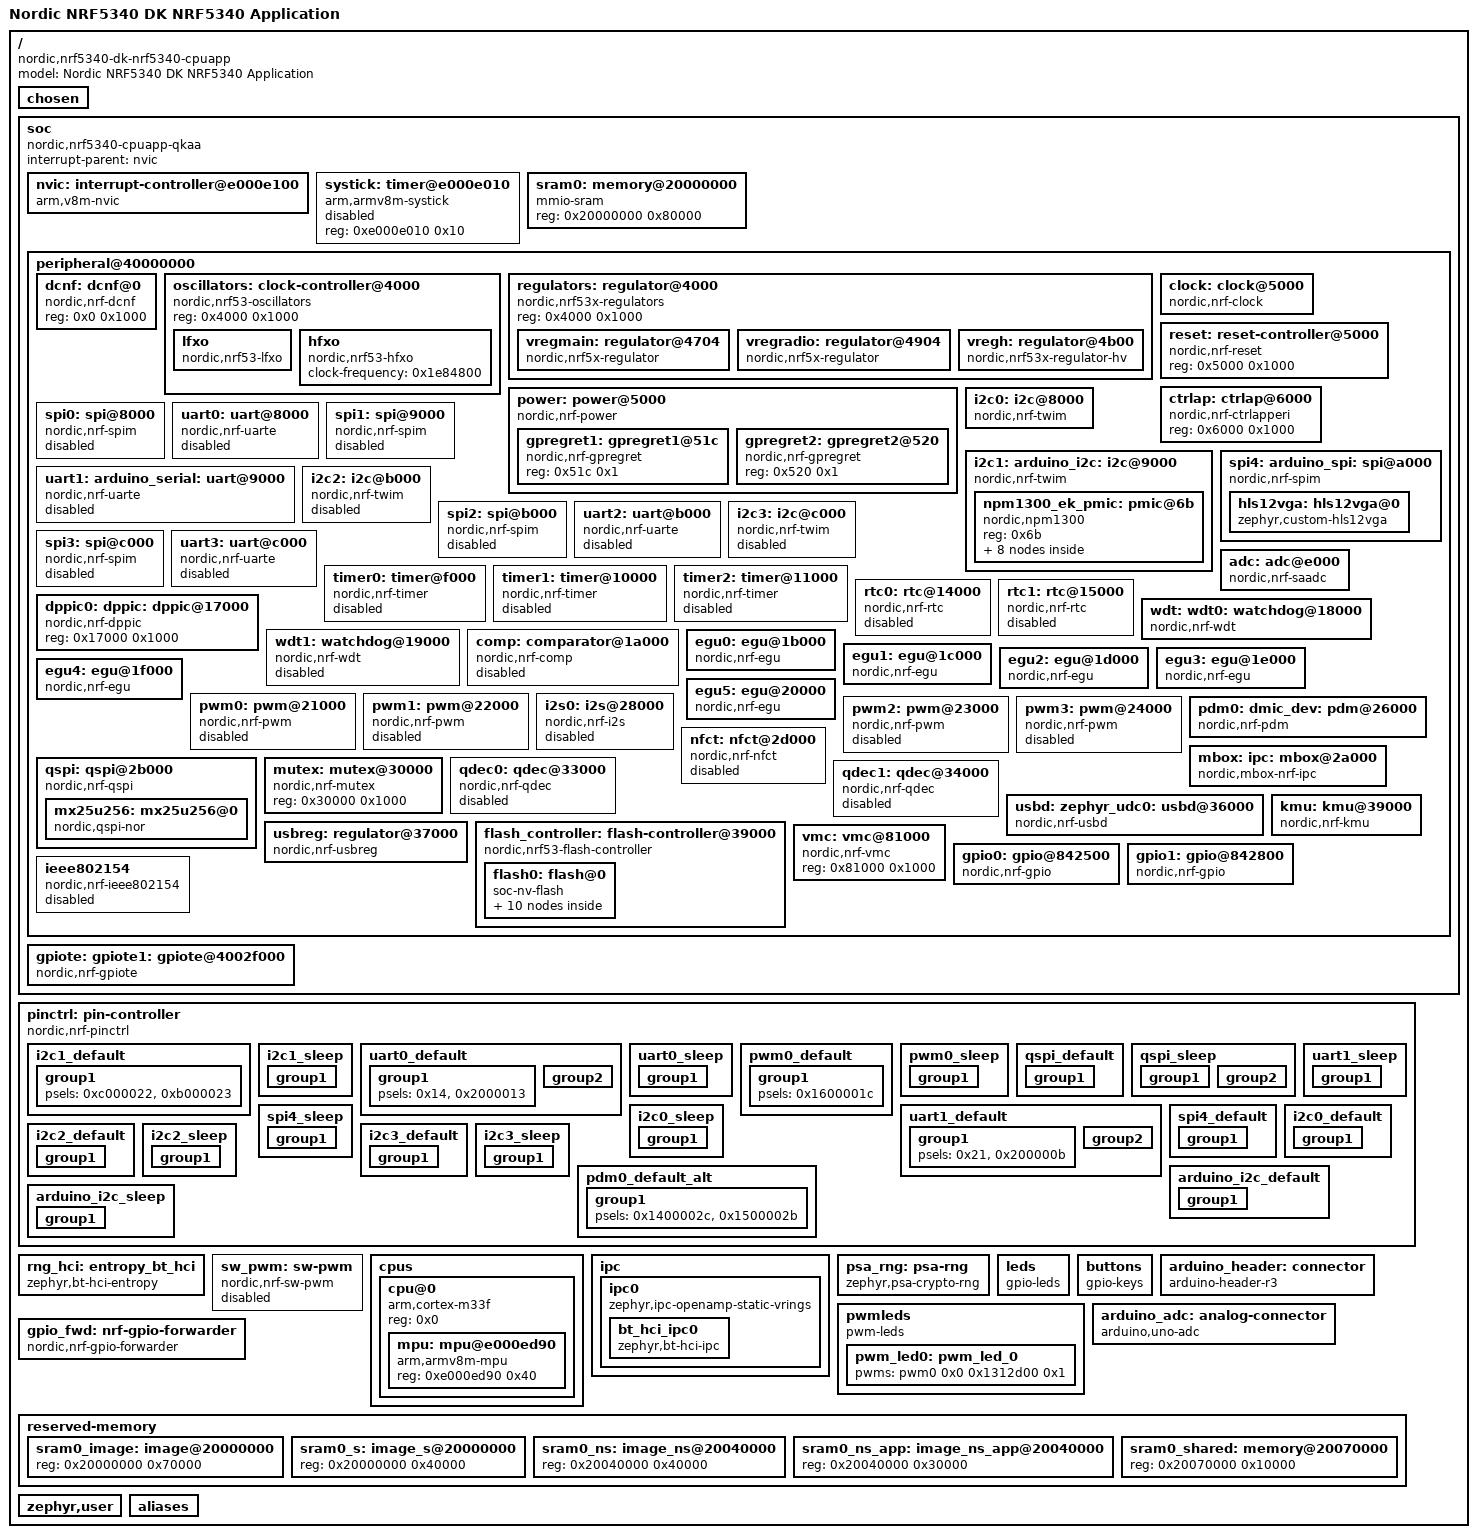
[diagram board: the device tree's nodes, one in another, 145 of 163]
/dts-v1/;

/ {
	#address-cells = < 0x1 >;
	#size-cells = < 0x1 >;
	model = "Nordic NRF5340 DK NRF5340 Application";
	compatible = "nordic,nrf5340-dk-nrf5340-cpuapp";
	chosen {
		zephyr,entropy = &psa_rng;
		zephyr,flash-controller = &flash_controller;
		zephyr,console = &uart0;
		zephyr,shell-uart = &uart0;
		zephyr,uart-mcumgr = &uart0;
		zephyr,bt-mon-uart = &uart0;
		zephyr,bt-c2h-uart = &uart0;
		zephyr,bt-hci = &bt_hci_ipc0;
		nordic,802154-spinel-ipc = &ipc0;
		zephyr,ieee802154 = &ieee802154;
		zephyr,ipc_shm = &sram0_shared;
		zephyr,sram = &sram0_ns_app;
		zephyr,flash = &flash0;
		zephyr,code-partition = &slot0_ns_partition;
		zephyr,display = &hls12vga;
		nordic,pm-ext-flash = &mx25u256;
	};
	soc {
		#address-cells = < 0x1 >;
		#size-cells = < 0x1 >;
		compatible = "nordic,nrf5340-cpuapp-qkaa", "nordic,nrf5340-cpuapp", "nordic,nrf53", "simple-bus";
		interrupt-parent = < &nvic >;
		ranges;
		nvic: interrupt-controller@e000e100 {
			#address-cells = < 0x1 >;
			compatible = "arm,v8m-nvic";
			reg = < 0xe000e100 0xc00 >;
			interrupt-controller;
			#interrupt-cells = < 0x2 >;
			arm,num-irq-priority-bits = < 0x3 >;
			phandle = < 0x1 >;
		};
		systick: timer@e000e010 {
			compatible = "arm,armv8m-systick";
			reg = < 0xe000e010 0x10 >;
			status = "disabled";
		};
		sram0: memory@20000000 {
			compatible = "mmio-sram";
			reg = < 0x20000000 0x80000 >;
		};
		peripheral@40000000 {
			#address-cells = < 0x1 >;
			#size-cells = < 0x1 >;
			ranges = < 0x0 0x40000000 0x10000000 >;
			dcnf: dcnf@0 {
				compatible = "nordic,nrf-dcnf";
				reg = < 0x0 0x1000 >;
				status = "okay";
			};
			oscillators: clock-controller@4000 {
				compatible = "nordic,nrf53-oscillators";
				reg = < 0x4000 0x1000 >;
				lfxo: lfxo {
					compatible = "nordic,nrf53-lfxo";
					#clock-cells = < 0x0 >;
					clock-frequency = < 0x8000 >;
					load-capacitors = "internal";
					load-capacitance-picofarad = < 0x7 >;
				};
				hfxo: hfxo {
					compatible = "nordic,nrf53-hfxo";
					#clock-cells = < 0x0 >;
					clock-frequency = < 0x1e84800 >;
				};
			};
			regulators: regulator@4000 {
				compatible = "nordic,nrf53x-regulators";
				reg = < 0x4000 0x1000 >;
				status = "okay";
				#address-cells = < 0x1 >;
				#size-cells = < 0x1 >;
				vregmain: regulator@4704 {
					compatible = "nordic,nrf5x-regulator";
					reg = < 0x4704 0x1 >;
					status = "okay";
					regulator-name = "VREGMAIN";
					regulator-initial-mode = < 0x1 >;
				};
				vregradio: regulator@4904 {
					compatible = "nordic,nrf5x-regulator";
					reg = < 0x4904 0x1 >;
					status = "okay";
					regulator-name = "VREGRADIO";
					regulator-initial-mode = < 0x1 >;
				};
				vregh: regulator@4b00 {
					compatible = "nordic,nrf53x-regulator-hv";
					reg = < 0x4b00 0x44 >;
					status = "okay";
					regulator-name = "VREGH";
				};
			};
			clock: clock@5000 {
				compatible = "nordic,nrf-clock";
				reg = < 0x5000 0x1000 >;
				interrupts = < 0x5 0x1 >;
				status = "okay";
			};
			power: power@5000 {
				compatible = "nordic,nrf-power";
				reg = < 0x5000 0x1000 >;
				ranges = < 0x0 0x5000 0x1000 >;
				interrupts = < 0x5 0x1 >;
				status = "okay";
				#address-cells = < 0x1 >;
				#size-cells = < 0x1 >;
				gpregret1: gpregret1@51c {
					#address-cells = < 0x1 >;
					#size-cells = < 0x1 >;
					compatible = "nordic,nrf-gpregret";
					reg = < 0x51c 0x1 >;
					status = "okay";
				};
				gpregret2: gpregret2@520 {
					#address-cells = < 0x1 >;
					#size-cells = < 0x1 >;
					compatible = "nordic,nrf-gpregret";
					reg = < 0x520 0x1 >;
					status = "okay";
				};
			};
			reset: reset-controller@5000 {
				compatible = "nordic,nrf-reset";
				reg = < 0x5000 0x1000 >;
				status = "okay";
			};
			ctrlap: ctrlap@6000 {
				compatible = "nordic,nrf-ctrlapperi";
				reg = < 0x6000 0x1000 >;
				status = "okay";
			};
			i2c0: i2c@8000 {
				compatible = "nordic,nrf-twim";
				#address-cells = < 0x1 >;
				#size-cells = < 0x0 >;
				reg = < 0x8000 0x1000 >;
				interrupts = < 0x8 0x1 >;
				easydma-maxcnt-bits = < 0x10 >;
				status = "okay";
				zephyr,pm-device-runtime-auto;
				pinctrl-0 = < &i2c0_default >;
				pinctrl-1 = < &i2c0_sleep >;
				pinctrl-names = "default", "sleep";
			};
			spi0: spi@8000 {
				compatible = "nordic,nrf-spim";
				#address-cells = < 0x1 >;
				#size-cells = < 0x0 >;
				reg = < 0x8000 0x1000 >;
				interrupts = < 0x8 0x1 >;
				max-frequency = < 0x7a1200 >;
				easydma-maxcnt-bits = < 0x10 >;
				status = "disabled";
			};
			uart0: uart@8000 {
				compatible = "nordic,nrf-uarte";
				reg = < 0x8000 0x1000 >;
				interrupts = < 0x8 0x1 >;
				status = "disabled";
				current-speed = < 0x1c200 >;
				pinctrl-0 = < &uart0_default >;
				pinctrl-1 = < &uart0_sleep >;
				pinctrl-names = "default", "sleep";
			};
			i2c1: arduino_i2c: i2c@9000 {
				compatible = "nordic,nrf-twim";
				#address-cells = < 0x1 >;
				#size-cells = < 0x0 >;
				reg = < 0x9000 0x1000 >;
				interrupts = < 0x9 0x1 >;
				easydma-maxcnt-bits = < 0x10 >;
				status = "okay";
				zephyr,pm-device-runtime-auto;
				pinctrl-0 = < &arduino_i2c_default >;
				pinctrl-1 = < &arduino_i2c_sleep >;
				pinctrl-names = "default", "sleep";
				clock-frequency = < 0x186a0 >;
				npm1300_ek_pmic: pmic@6b {
					compatible = "nordic,npm1300";
					reg = < 0x6b >;
					npm1300_ek_gpio: gpio-controller {
						compatible = "nordic,npm1300-gpio";
						gpio-controller;
						#gpio-cells = < 0x2 >;
						ngpios = < 0x5 >;
					};
					npm1300_ek_regulators: regulators {
						compatible = "nordic,npm1300-regulator";
						npm1300_ek_buck1: BUCK1 {
							regulator-min-microvolt = < 0xf4240 >;
							regulator-max-microvolt = < 0x325aa0 >;
							retention-microvolt = < 0x124f80 >;
						};
						npm1300_ek_buck2: BUCK2 {
							regulator-min-microvolt = < 0xf4240 >;
							regulator-max-microvolt = < 0x325aa0 >;
							retention-microvolt = < 0x1b7740 >;
						};
						npm1300_ek_ldo1: LDO1 {
							regulator-min-microvolt = < 0xf4240 >;
							regulator-max-microvolt = < 0x325aa0 >;
							regulator-initial-mode = < 0x3 >;
							regulator-boot-on;
						};
						npm1300_ek_ldo2: LDO2 {
							regulator-min-microvolt = < 0xf4240 >;
							regulator-max-microvolt = < 0x325aa0 >;
							regulator-initial-mode = < 0x3 >;
							regulator-boot-on;
						};
					};
					npm1300_ek_charger: charger {
						compatible = "nordic,npm1300-charger";
						term-microvolt = < 0x40d990 >;
						term-warm-microvolt = < 0x36ee80 >;
						current-microamp = < 0xc3500 >;
						dischg-limit-microamp = < 0x30d40 >;
						vbus-limit-microamp = < 0x7a120 >;
						thermistor-ohms = < 0x2710 >;
						thermistor-beta = < 0xd34 >;
						charging-enable;
						vbatlow-charge-enable;
					};
					npm1300_ek_leds: leds {
						compatible = "nordic,npm1300-led";
						nordic,led0-mode = "error";
						nordic,led1-mode = "charging";
						nordic,led2-mode = "host";
					};
				};
			};
			spi1: spi@9000 {
				compatible = "nordic,nrf-spim";
				#address-cells = < 0x1 >;
				#size-cells = < 0x0 >;
				reg = < 0x9000 0x1000 >;
				interrupts = < 0x9 0x1 >;
				max-frequency = < 0x7a1200 >;
				easydma-maxcnt-bits = < 0x10 >;
				status = "disabled";
			};
			uart1: arduino_serial: uart@9000 {
				compatible = "nordic,nrf-uarte";
				reg = < 0x9000 0x1000 >;
				interrupts = < 0x9 0x1 >;
				status = "disabled";
				current-speed = < 0x1c200 >;
				pinctrl-0 = < &uart1_default >;
				pinctrl-1 = < &uart1_sleep >;
				pinctrl-names = "default", "sleep";
			};
			spi4: arduino_spi: spi@a000 {
				compatible = "nordic,nrf-spim";
				#address-cells = < 0x1 >;
				#size-cells = < 0x0 >;
				reg = < 0xa000 0x1000 >;
				interrupts = < 0xa 0x1 >;
				max-frequency = < 0x1e84800 >;
				easydma-maxcnt-bits = < 0x10 >;
				rx-delay-supported;
				rx-delay = < 0x2 >;
				status = "okay";
				cs-gpios = < &gpio0 0x0 0x0 >;
				pinctrl-0 = < &spi4_default >;
				pinctrl-1 = < &spi4_sleep >;
				pinctrl-names = "default", "sleep";
				hls12vga: hls12vga@0 {
					compatible = "zephyr,custom-hls12vga";
					status = "okay";
					reg = < 0x0 >;
					spi-max-frequency = < 0x1e84800 >;
					left_cs-gpios = < &gpio0 0xb 0x0 >;
					right_cs-gpios = < &gpio0 0xc 0x0 >;
					reset-gpios = < &gpio1 0x1 0x0 >;
					vcom-gpios = < &gpio0 0x7 0x0 >;
					v1_8-gpios = < &gpio0 0x6 0x0 >;
					v0_9-gpios = < &gpio0 0x5 0x0 >;
					width = < 0x280 >;
					height = < 0x1e0 >;
				};
			};
			i2c2: i2c@b000 {
				compatible = "nordic,nrf-twim";
				#address-cells = < 0x1 >;
				#size-cells = < 0x0 >;
				reg = < 0xb000 0x1000 >;
				interrupts = < 0xb 0x1 >;
				easydma-maxcnt-bits = < 0x10 >;
				status = "disabled";
				zephyr,pm-device-runtime-auto;
				pinctrl-0 = < &i2c2_default >;
				pinctrl-1 = < &i2c2_sleep >;
				pinctrl-names = "default", "sleep";
			};
			spi2: spi@b000 {
				compatible = "nordic,nrf-spim";
				#address-cells = < 0x1 >;
				#size-cells = < 0x0 >;
				reg = < 0xb000 0x1000 >;
				interrupts = < 0xb 0x1 >;
				max-frequency = < 0x7a1200 >;
				easydma-maxcnt-bits = < 0x10 >;
				status = "disabled";
			};
			uart2: uart@b000 {
				compatible = "nordic,nrf-uarte";
				reg = < 0xb000 0x1000 >;
				interrupts = < 0xb 0x1 >;
				status = "disabled";
			};
			i2c3: i2c@c000 {
				compatible = "nordic,nrf-twim";
				#address-cells = < 0x1 >;
				#size-cells = < 0x0 >;
				reg = < 0xc000 0x1000 >;
				interrupts = < 0xc 0x1 >;
				easydma-maxcnt-bits = < 0x10 >;
				status = "disabled";
				zephyr,pm-device-runtime-auto;
				pinctrl-0 = < &i2c3_default >;
				pinctrl-1 = < &i2c3_sleep >;
				pinctrl-names = "default", "sleep";
			};
			spi3: spi@c000 {
				compatible = "nordic,nrf-spim";
				#address-cells = < 0x1 >;
				#size-cells = < 0x0 >;
				reg = < 0xc000 0x1000 >;
				interrupts = < 0xc 0x1 >;
				max-frequency = < 0x7a1200 >;
				easydma-maxcnt-bits = < 0x10 >;
				status = "disabled";
			};
			uart3: uart@c000 {
				compatible = "nordic,nrf-uarte";
				reg = < 0xc000 0x1000 >;
				interrupts = < 0xc 0x1 >;
				status = "disabled";
			};
			adc: adc@e000 {
				compatible = "nordic,nrf-saadc";
				reg = < 0xe000 0x1000 >;
				interrupts = < 0xe 0x1 >;
				status = "okay";
				#io-channel-cells = < 0x1 >;
				zephyr,pm-device-runtime-auto;
				phandle = < 0x1c >;
			};
			timer0: timer@f000 {
				compatible = "nordic,nrf-timer";
				status = "disabled";
				reg = < 0xf000 0x1000 >;
				cc-num = < 0x6 >;
				max-bit-width = < 0x20 >;
				interrupts = < 0xf 0x1 >;
				prescaler = < 0x0 >;
			};
			timer1: timer@10000 {
				compatible = "nordic,nrf-timer";
				status = "disabled";
				reg = < 0x10000 0x1000 >;
				cc-num = < 0x6 >;
				max-bit-width = < 0x20 >;
				interrupts = < 0x10 0x1 >;
				prescaler = < 0x0 >;
				phandle = < 0x18 >;
			};
			timer2: timer@11000 {
				compatible = "nordic,nrf-timer";
				status = "disabled";
				reg = < 0x11000 0x1000 >;
				cc-num = < 0x6 >;
				max-bit-width = < 0x20 >;
				interrupts = < 0x11 0x1 >;
				prescaler = < 0x0 >;
			};
			rtc0: rtc@14000 {
				compatible = "nordic,nrf-rtc";
				reg = < 0x14000 0x1000 >;
				cc-num = < 0x4 >;
				interrupts = < 0x14 0x1 >;
				status = "disabled";
				clock-frequency = < 0x8000 >;
				prescaler = < 0x1 >;
			};
			rtc1: rtc@15000 {
				compatible = "nordic,nrf-rtc";
				reg = < 0x15000 0x1000 >;
				cc-num = < 0x4 >;
				interrupts = < 0x15 0x1 >;
				status = "disabled";
				clock-frequency = < 0x8000 >;
				prescaler = < 0x1 >;
			};
			dppic0: dppic: dppic@17000 {
				compatible = "nordic,nrf-dppic";
				reg = < 0x17000 0x1000 >;
				status = "okay";
			};
			wdt: wdt0: watchdog@18000 {
				compatible = "nordic,nrf-wdt";
				reg = < 0x18000 0x1000 >;
				interrupts = < 0x18 0x1 >;
				status = "okay";
			};
			wdt1: watchdog@19000 {
				compatible = "nordic,nrf-wdt";
				reg = < 0x19000 0x1000 >;
				interrupts = < 0x19 0x1 >;
				status = "disabled";
			};
			comp: comparator@1a000 {
				compatible = "nordic,nrf-comp";
				reg = < 0x1a000 0x1000 >;
				interrupts = < 0x1a 0x1 >;
				status = "disabled";
			};
			egu0: egu@1b000 {
				compatible = "nordic,nrf-egu";
				reg = < 0x1b000 0x1000 >;
				interrupts = < 0x1b 0x1 >;
				status = "okay";
			};
			egu1: egu@1c000 {
				compatible = "nordic,nrf-egu";
				reg = < 0x1c000 0x1000 >;
				interrupts = < 0x1c 0x1 >;
				status = "okay";
			};
			egu2: egu@1d000 {
				compatible = "nordic,nrf-egu";
				reg = < 0x1d000 0x1000 >;
				interrupts = < 0x1d 0x1 >;
				status = "okay";
			};
			egu3: egu@1e000 {
				compatible = "nordic,nrf-egu";
				reg = < 0x1e000 0x1000 >;
				interrupts = < 0x1e 0x1 >;
				status = "okay";
			};
			egu4: egu@1f000 {
				compatible = "nordic,nrf-egu";
				reg = < 0x1f000 0x1000 >;
				interrupts = < 0x1f 0x1 >;
				status = "okay";
			};
			egu5: egu@20000 {
				compatible = "nordic,nrf-egu";
				reg = < 0x20000 0x1000 >;
				interrupts = < 0x20 0x1 >;
				status = "okay";
			};
			pwm0: pwm@21000 {
				compatible = "nordic,nrf-pwm";
				reg = < 0x21000 0x1000 >;
				interrupts = < 0x21 0x1 >;
				status = "disabled";
				#pwm-cells = < 0x3 >;
				pinctrl-0 = < &pwm0_default >;
				pinctrl-1 = < &pwm0_sleep >;
				pinctrl-names = "default", "sleep";
				phandle = < 0x1b >;
			};
			pwm1: pwm@22000 {
				compatible = "nordic,nrf-pwm";
				reg = < 0x22000 0x1000 >;
				interrupts = < 0x22 0x1 >;
				status = "disabled";
				#pwm-cells = < 0x3 >;
			};
			pwm2: pwm@23000 {
				compatible = "nordic,nrf-pwm";
				reg = < 0x23000 0x1000 >;
				interrupts = < 0x23 0x1 >;
				status = "disabled";
				#pwm-cells = < 0x3 >;
			};
			pwm3: pwm@24000 {
				compatible = "nordic,nrf-pwm";
				reg = < 0x24000 0x1000 >;
				interrupts = < 0x24 0x1 >;
				status = "disabled";
				#pwm-cells = < 0x3 >;
			};
			pdm0: dmic_dev: pdm@26000 {
				compatible = "nordic,nrf-pdm";
				reg = < 0x26000 0x1000 >;
				interrupts = < 0x26 0x1 >;
				status = "okay";
				pinctrl-0 = < &pdm0_default_alt >;
				pinctrl-names = "default";
			};
			i2s0: i2s@28000 {
				compatible = "nordic,nrf-i2s";
				#address-cells = < 0x1 >;
				#size-cells = < 0x0 >;
				reg = < 0x28000 0x1000 >;
				interrupts = < 0x28 0x1 >;
				status = "disabled";
			};
			mbox: ipc: mbox@2a000 {
				compatible = "nordic,mbox-nrf-ipc", "nordic,nrf-ipc";
				reg = < 0x2a000 0x1000 >;
				tx-mask = < 0xffff >;
				rx-mask = < 0xffff >;
				interrupts = < 0x2a 0x1 >;
				#mbox-cells = < 0x1 >;
				status = "okay";
				phandle = < 0x1a >;
			};
			qspi: qspi@2b000 {
				compatible = "nordic,nrf-qspi";
				#address-cells = < 0x1 >;
				#size-cells = < 0x0 >;
				reg = < 0x2b000 0x1000 >, < 0x10000000 0x10000000 >;
				reg-names = "qspi", "qspi_mm";
				interrupts = < 0x2b 0x1 >;
				status = "okay";
				pinctrl-0 = < &qspi_default >;
				pinctrl-1 = < &qspi_sleep >;
				pinctrl-names = "default", "sleep";
				mx25u256: mx25u256@0 {
					compatible = "nordic,qspi-nor";
					reg = < 0x0 >;
					writeoc = "pp4io";
					readoc = "read4io";
					sck-frequency = < 0x1e84800 >;
					address-size-32;
					enter-4byte-addr = < 0xb7 >;
					jedec-id = [ C2 25 39 ];
					sfdp-bfp = [ E5 20 FB FF FF FF FF 0F 44 EB 08 6B 08 3B 04 BB FE FF FF FF FF FF 00 FF FF FF 44 EB 0C 20 0F 52 10 D8 00 FF 25 52 DD 00 84 A5 04 E2 44 03 17 38 30 B0 30 B0 F7 BD D5 5C 4A 9E 29 FF F0 50 F9 85 ];
					size = < 0x2000000 >;
					has-dpd;
					t-enter-dpd = < 0x2710 >;
					t-exit-dpd = < 0x88b8 >;
				};
			};
			nfct: nfct@2d000 {
				compatible = "nordic,nrf-nfct";
				reg = < 0x2d000 0x1000 >;
				interrupts = < 0x2d 0x1 >;
				status = "disabled";
			};
			mutex: mutex@30000 {
				compatible = "nordic,nrf-mutex";
				reg = < 0x30000 0x1000 >;
				status = "okay";
			};
			qdec0: qdec@33000 {
				compatible = "nordic,nrf-qdec";
				reg = < 0x33000 0x1000 >;
				interrupts = < 0x33 0x1 >;
				status = "disabled";
			};
			qdec1: qdec@34000 {
				compatible = "nordic,nrf-qdec";
				reg = < 0x34000 0x1000 >;
				interrupts = < 0x34 0x1 >;
				status = "disabled";
			};
			usbd: zephyr_udc0: usbd@36000 {
				compatible = "nordic,nrf-usbd";
				reg = < 0x36000 0x1000 >;
				interrupts = < 0x36 0x1 >;
				num-bidir-endpoints = < 0x1 >;
				num-in-endpoints = < 0x7 >;
				num-out-endpoints = < 0x7 >;
				num-isoin-endpoints = < 0x1 >;
				num-isoout-endpoints = < 0x1 >;
				status = "okay";
			};
			usbreg: regulator@37000 {
				compatible = "nordic,nrf-usbreg";
				reg = < 0x37000 0x1000 >;
				interrupts = < 0x37 0x1 >;
				status = "okay";
			};
			flash_controller: flash-controller@39000 {
				compatible = "nordic,nrf53-flash-controller";
				reg = < 0x39000 0x1000 >;
				partial-erase;
				#address-cells = < 0x1 >;
				#size-cells = < 0x1 >;
				flash0: flash@0 {
					compatible = "soc-nv-flash";
					erase-block-size = < 0x1000 >;
					write-block-size = < 0x4 >;
					reg = < 0x0 0x100000 >;
					partitions {
						compatible = "fixed-partitions";
						#address-cells = < 0x1 >;
						#size-cells = < 0x1 >;
						boot_partition: partition@0 {
							label = "mcuboot";
							reg = < 0x0 0x10000 >;
						};
						slot0_partition: partition@10000 {
							label = "image-0";
							reg = < 0x10000 0x40000 >;
						};
						slot0_ns_partition: partition@50000 {
							label = "image-0-nonsecure";
							reg = < 0x50000 0x30000 >;
						};
						slot1_partition: partition@80000 {
							label = "image-1";
							reg = < 0x80000 0x40000 >;
						};
						slot1_ns_partition: partition@c0000 {
							label = "image-1-nonsecure";
							reg = < 0xc0000 0x30000 >;
						};
						tfm_ps_partition: partition@f0000 {
							label = "tfm-ps";
							reg = < 0xf0000 0x4000 >;
						};
						tfm_its_partition: partition@f4000 {
							label = "tfm-its";
							reg = < 0xf4000 0x2000 >;
						};
						tfm_otp_partition: partition@f6000 {
							label = "tfm-otp";
							reg = < 0xf6000 0x2000 >;
						};
						storage_partition: partition@f8000 {
							label = "storage";
							reg = < 0xf8000 0x8000 >;
						};
					};
				};
			};
			kmu: kmu@39000 {
				compatible = "nordic,nrf-kmu";
				reg = < 0x39000 0x1000 >;
				interrupts = < 0x39 0x1 >;
				status = "okay";
			};
			vmc: vmc@81000 {
				compatible = "nordic,nrf-vmc";
				reg = < 0x81000 0x1000 >;
				status = "okay";
			};
			gpio0: gpio@842500 {
				compatible = "nordic,nrf-gpio";
				gpio-controller;
				reg = < 0x842500 0x300 >;
				#gpio-cells = < 0x2 >;
				status = "okay";
				port = < 0x0 >;
				gpiote-instance = < &gpiote >;
				sense-edge-mask = < 0xffffffff >;
				phandle = < 0xa >;
			};
			gpio1: gpio@842800 {
				compatible = "nordic,nrf-gpio";
				gpio-controller;
				reg = < 0x842800 0x300 >;
				#gpio-cells = < 0x2 >;
				ngpios = < 0x10 >;
				status = "okay";
				port = < 0x1 >;
				gpiote-instance = < &gpiote >;
				sense-edge-mask = < 0xffffffff >;
				phandle = < 0xd >;
			};
			ieee802154: ieee802154 {
				compatible = "nordic,nrf-ieee802154";
				status = "disabled";
			};
		};
		gpiote: gpiote1: gpiote@4002f000 {
			compatible = "nordic,nrf-gpiote";
			reg = < 0x4002f000 0x1000 >;
			interrupts = < 0x2f 0x5 >;
			status = "okay";
			instance = < 0x1 >;
			phandle = < 0x17 >;
		};
	};
	pinctrl: pin-controller {
		compatible = "nordic,nrf-pinctrl";
		i2c1_default: i2c1_default {
			group1 {
				psels = < 0xc000022 >, < 0xb000023 >;
			};
		};
		i2c1_sleep: i2c1_sleep {
			group1 {
				psels = < 0xc000022 >, < 0xb000023 >;
				low-power-enable;
			};
		};
		uart0_default: uart0_default {
			phandle = < 0x4 >;
			group1 {
				psels = < 0x14 >, < 0x2000013 >;
			};
			group2 {
				psels = < 0x1000016 >, < 0x3000015 >;
				bias-pull-up;
			};
		};
		uart0_sleep: uart0_sleep {
			phandle = < 0x5 >;
			group1 {
				psels = < 0x14 >, < 0x1000016 >, < 0x2000013 >, < 0x3000015 >;
				low-power-enable;
			};
		};
		pwm0_default: pwm0_default {
			phandle = < 0x12 >;
			group1 {
				psels = < 0x1600001c >;
			};
		};
		pwm0_sleep: pwm0_sleep {
			phandle = < 0x13 >;
			group1 {
				psels = < 0x1600001c >;
				low-power-enable;
			};
		};
		qspi_default: qspi_default {
			phandle = < 0x15 >;
			group1 {
				psels = < 0x1d000011 >, < 0x1f00000d >, < 0x2000000e >, < 0x2100000f >, < 0x22000010 >, < 0x1e000012 >;
				nordic,drive-mode = < 0x3 >;
			};
		};
		qspi_sleep: qspi_sleep {
			phandle = < 0x16 >;
			group1 {
				psels = < 0x1d000011 >, < 0x1f00000d >, < 0x2000000e >, < 0x2100000f >, < 0x22000010 >;
				low-power-enable;
			};
			group2 {
				psels = < 0x1e000012 >;
				low-power-enable;
				bias-pull-up;
			};
		};
		uart1_default: uart1_default {
			phandle = < 0x8 >;
			group1 {
				psels = < 0x21 >, < 0x200000b >;
			};
			group2 {
				psels = < 0x1000020 >, < 0x300000a >;
				bias-pull-up;
			};
		};
		uart1_sleep: uart1_sleep {
			phandle = < 0x9 >;
			group1 {
				psels = < 0x21 >, < 0x1000020 >, < 0x200000b >, < 0x300000a >;
				low-power-enable;
			};
		};
		spi4_default: spi4_default {
			phandle = < 0xb >;
			group1 {
				psels = < 0x4000008 >, < 0x600000a >, < 0x5000009 >;
				nordic,drive-mode = < 0x8 >;
			};
		};
		spi4_sleep: spi4_sleep {
			phandle = < 0xc >;
			group1 {
				psels = < 0x4000008 >, < 0x600000a >, < 0x5000009 >;
				low-power-enable;
			};
		};
		i2c0_default: i2c0_default {
			phandle = < 0x2 >;
			group1 {
				psels = < 0xc00001f >, < 0xb00001e >;
				bias-pull-up;
				nordic,drive-mode = < 0x6 >;
			};
		};
		i2c0_sleep: i2c0_sleep {
			phandle = < 0x3 >;
			group1 {
				psels = < 0xc00001f >, < 0xb00001e >;
				low-power-enable;
			};
		};
		i2c2_default: i2c2_default {
			phandle = < 0xe >;
			group1 {
				psels = < 0xc00002f >, < 0xb00002e >;
				bias-pull-up;
				nordic,drive-mode = < 0x6 >;
			};
		};
		i2c2_sleep: i2c2_sleep {
			phandle = < 0xf >;
			group1 {
				psels = < 0xc00002f >, < 0xb00002e >;
				low-power-enable;
			};
		};
		i2c3_default: i2c3_default {
			phandle = < 0x10 >;
			group1 {
				psels = < 0xc000024 >, < 0xb000025 >;
				bias-pull-up;
				nordic,drive-mode = < 0x6 >;
			};
		};
		i2c3_sleep: i2c3_sleep {
			phandle = < 0x11 >;
			group1 {
				psels = < 0xc000024 >, < 0xb000025 >;
				low-power-enable;
			};
		};
		pdm0_default_alt: pdm0_default_alt {
			phandle = < 0x14 >;
			group1 {
				psels = < 0x1400002c >, < 0x1500002b >;
			};
		};
		arduino_i2c_default: arduino_i2c_default {
			phandle = < 0x6 >;
			group1 {
				psels = < 0xb00001d >, < 0xc00002a >;
				bias-pull-up;
			};
		};
		arduino_i2c_sleep: arduino_i2c_sleep {
			phandle = < 0x7 >;
			group1 {
				psels = < 0xb00001d >, < 0xc00002a >;
				low-power-enable;
			};
		};
	};
	rng_hci: entropy_bt_hci {
		compatible = "zephyr,bt-hci-entropy";
		status = "okay";
	};
	sw_pwm: sw-pwm {
		compatible = "nordic,nrf-sw-pwm";
		status = "disabled";
		generator = < &timer1 >;
		clock-prescaler = < 0x0 >;
		#pwm-cells = < 0x3 >;
	};
	cpus {
		#address-cells = < 0x1 >;
		#size-cells = < 0x0 >;
		cpu@0 {
			device_type = "cpu";
			compatible = "arm,cortex-m33f";
			reg = < 0x0 >;
			#address-cells = < 0x1 >;
			#size-cells = < 0x1 >;
			mpu: mpu@e000ed90 {
				compatible = "arm,armv8m-mpu";
				reg = < 0xe000ed90 0x40 >;
			};
		};
	};
	ipc {
		ipc0: ipc0 {
			compatible = "zephyr,ipc-openamp-static-vrings";
			memory-region = < &sram0_shared >;
			mboxes = < &mbox 0x0 >, < &mbox 0x1 >;
			mbox-names = "tx", "rx";
			role = "host";
			status = "okay";
			bt_hci_ipc0: bt_hci_ipc0 {
				compatible = "zephyr,bt-hci-ipc";
				status = "okay";
			};
		};
	};
	psa_rng: psa-rng {
		compatible = "zephyr,psa-crypto-rng";
		status = "okay";
	};
	leds {
		compatible = "gpio-leds";
	};
	buttons {
		compatible = "gpio-keys";
	};
	arduino_header: connector {
		compatible = "arduino-header-r3";
		#gpio-cells = < 0x2 >;
		gpio-map-mask = < 0xffffffff 0xffffffc0 >;
		gpio-map-pass-thru = < 0x0 0x3f >;
		gpio-map = < 0x0 0x0 &gpio0 0x4 0x0 >, < 0x1 0x0 &gpio0 0x5 0x0 >, < 0x2 0x0 &gpio0 0x6 0x0 >, < 0x3 0x0 &gpio0 0x7 0x0 >, < 0x4 0x0 &gpio0 0x19 0x0 >, < 0x5 0x0 &gpio0 0x1a 0x0 >, < 0x6 0x0 &gpio1 0x0 0x0 >, < 0x7 0x0 &gpio1 0x1 0x0 >, < 0x8 0x0 &gpio1 0x4 0x0 >, < 0x9 0x0 &gpio1 0x5 0x0 >, < 0xa 0x0 &gpio1 0x6 0x0 >, < 0xb 0x0 &gpio1 0x7 0x0 >, < 0xc 0x0 &gpio1 0x8 0x0 >, < 0xd 0x0 &gpio1 0x9 0x0 >, < 0xe 0x0 &gpio1 0xa 0x0 >, < 0xf 0x0 &gpio1 0xb 0x0 >, < 0x10 0x0 &gpio1 0xc 0x0 >, < 0x11 0x0 &gpio1 0xd 0x0 >, < 0x12 0x0 &gpio1 0xe 0x0 >, < 0x13 0x0 &gpio1 0xf 0x0 >, < 0x14 0x0 &gpio1 0x2 0x0 >, < 0x15 0x0 &gpio1 0x3 0x0 >;
	};
	pwmleds {
		compatible = "pwm-leds";
		pwm_led0: pwm_led_0 {
			pwms = < &pwm0 0x0 0x1312d00 0x1 >;
		};
	};
	arduino_adc: analog-connector {
		compatible = "arduino,uno-adc";
		#io-channel-cells = < 0x1 >;
		io-channel-map = < 0x0 &adc 0x0 >, < 0x1 &adc 0x1 >, < 0x2 &adc 0x2 >, < 0x3 &adc 0x3 >, < 0x4 &adc 0x4 >, < 0x5 &adc 0x5 >;
	};
	gpio_fwd: nrf-gpio-forwarder {
		compatible = "nordic,nrf-gpio-forwarder";
		status = "okay";
	};
	reserved-memory {
		#address-cells = < 0x1 >;
		#size-cells = < 0x1 >;
		ranges;
		sram0_image: image@20000000 {
			reg = < 0x20000000 0x70000 >;
		};
		sram0_s: image_s@20000000 {
			reg = < 0x20000000 0x40000 >;
		};
		sram0_ns: image_ns@20040000 {
			reg = < 0x20040000 0x40000 >;
		};
		sram0_ns_app: image_ns_app@20040000 {
			reg = < 0x20040000 0x30000 >;
		};
		sram0_shared: memory@20070000 {
			reg = < 0x20070000 0x10000 >;
			phandle = < 0x19 >;
		};
	};
	zephyr,user {
		gx8002_sda-gpios = < &gpio1 0x4 0x0 >;
		gx8002_scl-gpios = < &gpio1 0x5 0x0 >;
		gx8002_int4-gpios = < &gpio0 0x16 0x0 >;
		jsa_1147_sda-gpios = < &gpio1 0x3 0x0 >;
		jsa_1147_scl-gpios = < &gpio1 0x2 0x0 >;
		jsa_1147_int1-gpios = < &gpio1 0xd 0x0 >;
		es_power_en-gpios = < &gpio1 0x0 0x0 >;
		mic_pwr_en-gpios = < &gpio0 0x4 0x0 >;
		key1-gpios = < &gpio0 0x17 0x0 >;
	};
	aliases {
		myimu6 = &i2c0;
		myimu3 = &i2c2;
		watchdog0 = &wdt0;
	};
};
